# RA register map
Vendor: Renesas; Series: All Chips; File version: x.xx
Registers are 32-bit, read-write, reset 0x0 unless marked. A register's access mark holds for its fields unless they carry their own. Offsets are from the block's base; [hi:lo] are bit positions; {n}, {i} and the like mark numbered series.

## R_SRC — Sampling Rate Converter
Base 0x40048000
{0x0+4i} SRCFCTR[{i}] (i=0..5551) (reset mask 0xFFC00000) — Filter Coefficient Table [{i}]
  [21:0] SRCFCOE — Stores a filter coefficient value.
0x5FF0 SRCID wo — Input Data Register
  [31:0] SRCID — SRCID is a 32-bit writ-only register that is used to input the data before sampling rate conversion. All the bits are read as 0.
0x5FF4 SRCOD ro — Output Data Register
  [31:0] SRCOD — SRCOD is a 32-bit read-only register used to output the data after sampling rate conversion. The data in the 16-stage output data FIFO is read through SRCOD. When the number of data in the output data FIFO is zero after the start of conversion, the value previously read is read again.
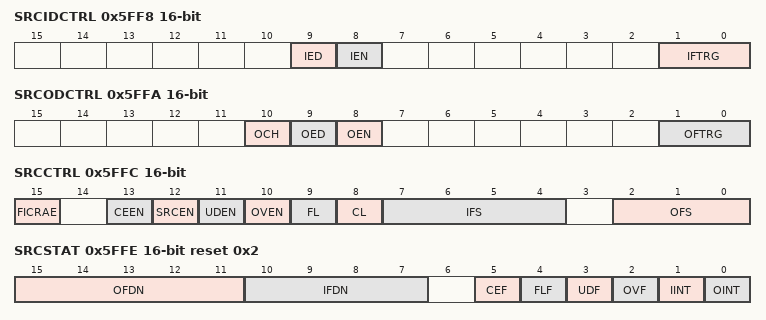
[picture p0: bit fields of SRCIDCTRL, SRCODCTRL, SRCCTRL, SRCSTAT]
0x5FF8 SRCIDCTRL 16-bit — Input Data Control Register
  [9] IED — Input Data Endian
    0=Endian formats 1 are the same between the CPU and input data; 1=Endian formats 1 are different between the CPU and input data
  [8] IEN — Input FIFO Empty Interrupt Enable
    0=Input FIFO empty interrupt is disabled; 1=Input FIFO empty interrupt is enabled
  [1:0] IFTRG — Input FIFO Data Triggering Number
    0=0; 1=2; 2=4; 3=6
0x5FFA SRCODCTRL 16-bit — Output Data Control Register
  [10] OCH — Output Data Channel Exchange
    0=Does not exchange the channels (the same order as data input); 1=Exchanges the channels (the opposite order from data input)
  [9] OED — Output Data Endian
    0=Endian formats are the same between the chip and input data; 1=Endian formats are different between the chip and input data
  [8] OEN — Output Data FIFO Full Interrupt Enable
    0=Output data FIFO full interrupt is disabled; 1=Output data FIFO full interrupt is enabled
  [1:0] OFTRG — Output FIFO Data Trigger Number
    0=1; 1=4; 2=8; 3=12
0x5FFC SRCCTRL 16-bit — Control Register
  [15] FICRAE — Filter Coefficient Table Access Enable
    0=Reading/writing to filter coefficient table RAM is disabled; 1=Reading/writing to filter coefficient table RAM is enabled
  [13] CEEN — Conversion End Interrupt Enable
    0=Disables conversion end interrupt requests; 1=Enables conversion end interrupt requests
  [12] SRCEN — Module Enable
    0=Disables this module operation; 1=Enables this module operation
  [11] UDEN — Output Data FIFO Underflow Interrupt Enable
    0=Disables output data FIFO underflow interrupt requests; 1=Enables output data FIFO underflow interrupt requests
  [10] OVEN — Output Data FIFO Overwrite Interrupt Enable
    0=Output data FIFO overwrite interrupt is disabled; 1=Output data FIFO overwrite interrupt is enabled
  [9] FL — Internal Work Memory Flush
    0=no effect; 1=starts converting the sampling rate of all the data in the input FIFO, input buffer memory, and intermediate memory(i.e., flush processing)
  [8] CL — Internal Work Memory Clear
    0=no effect; 1=Clears the input FIFO, output FIFO, input buffer memory, intermediate memory and accumulator
  [7:4] IFS — Input Sampling Rate
    0=8.0 kHz; 1=11.025 kHz; 2=12.0 kHz; 3=Setting prohibited; 4=16.0 kHz; 5=22.05 kHz; 6=24.0 kHz; 7=Setting prohibited; 8=32.0 kHz; 9=44.1 kHz; 10=48.0 kHz; other=others (Settings prohibited.)
  [2:0] OFS — Output Sampling Rate
    0=44.1 kHz; 1=48.0 kHz; 2=32.0 kHz; 3=Setting prohibited; 4=8.0 kHz ( Valid only when IFS[3:0] =1001b ); 5=16.0 kHz ( Valid only when IFS[3:0] =1001b ); other=others (Settings other than above are prohibited.)
0x5FFE SRCSTAT 16-bit reset 0x2 — Status Register
  [15:11] OFDN — Output FIFO Data CountIndicates the number of data units in the output FIFO.
  [10:7] IFDN — Input FIFO Data CountIndicates the number of data units in the input FIFO.
  [5] CEF write-0-clears read-modifies — Conversion End Flag
    0=All of the output data has not been read out; 1=All of the output data has been read out
  [4] FLF ro — Flush Processing Status Flag
    0=Flash processing is completed; 1=Flash processing is in progress
  [3] UDF write-0-clears read-modifies — Output FIFO Underflow Interrupt Request Flag
    0=Output data FIFO has not been read out; 1=Output data FIFO has been read out
  [2] OVF write-0-clears read-modifies — Output Data FIFO Overwrite Interrupt Request Flag
    0=Next data conversion processing is not completed; 1=Next data conversion processing is completed
  [1] IINT write-0-clears read-modifies — Input Data FIFO Empty Interrupt Request Flag
    0=Number of data units in the input FIFO has not become equal to or smaller than the specified triggering number; 1=Number of data units in the input FIFO has become equal to or smaller than the specified triggering number
  [0] OINT write-0-clears read-modifies — Output Data FIFO Full Interrupt Request Flag
    0=Number of data units in the output FIFO has not become equal to or greater than the specified triggering number; 1=Number of data units in the output FIFO has become equal to or greater than the specified triggering number
